VERSION ""

NS_ :

BS_:

BU_:
	NEO
	MCU
	GTW
	EPAS
	DI
	ESP
	SBW
	STW
	APP
	DAS
	XXX

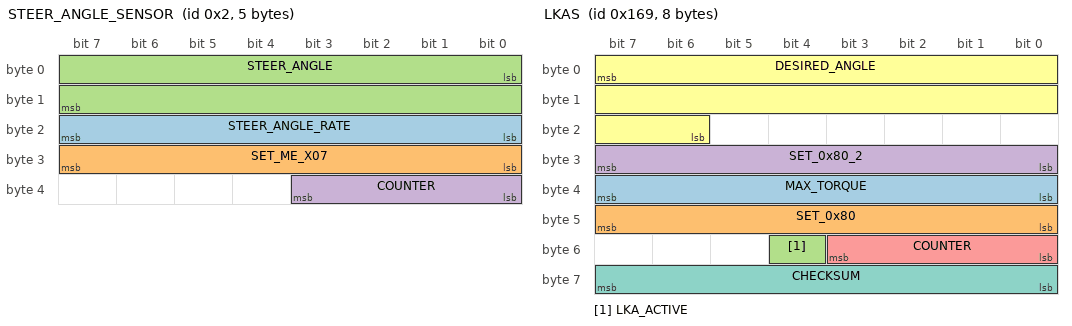
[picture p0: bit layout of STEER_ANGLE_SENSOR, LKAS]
BO_ 2 STEER_ANGLE_SENSOR: 5 XXX
 SG_ STEER_ANGLE_RATE : 16|8@1+ (1,0) [0|255] "" XXX
 SG_ SET_ME_X07 : 24|8@1+ (1,0) [0|255] "" XXX
 SG_ STEER_ANGLE : 0|16@1- (-0.1,0) [0|65535] "" XXX
 SG_ COUNTER : 32|4@1+ (1,0) [0|15] "" XXX

BO_ 361 LKAS: 8 XXX
 SG_ MAX_TORQUE : 39|8@0+ (0.01,0) [0|255] "Nm" XXX
 SG_ SET_0x80 : 47|8@0+ (1,0) [0|255] "" XXX
 SG_ LKA_ACTIVE : 52|1@0+ (1,0) [0|15] "" XXX
 SG_ SET_0x80_2 : 31|8@0+ (1,0) [0|255] "" XXX
 SG_ COUNTER : 51|4@0+ (1,0) [0|15] "" XXX
 SG_ DESIRED_ANGLE : 7|18@0+ (-0.01,1310) [-1311.43|1310] "" XXX
 SG_ CHECKSUM : 63|8@0+ (1,0) [0|255] "" XXX

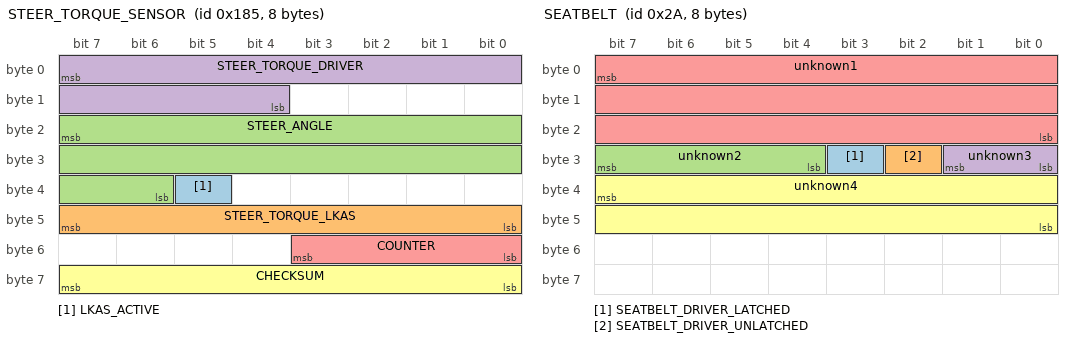
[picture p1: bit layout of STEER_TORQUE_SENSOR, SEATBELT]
BO_ 389 STEER_TORQUE_SENSOR: 8 XXX
 SG_ LKAS_ACTIVE : 37|1@0+ (1,0) [0|3] "" XXX
 SG_ STEER_TORQUE_LKAS : 47|8@0+ (1,0) [0|255] "" XXX
 SG_ STEER_ANGLE : 23|18@0+ (-0.01,1310) [0|262143] "" XXX
 SG_ STEER_TORQUE_DRIVER : 7|12@0+ (-0.01,20.47) [0|4095] "Nm" XXX
 SG_ COUNTER : 51|4@0+ (1,0) [0|15] "" XXX
 SG_ CHECKSUM : 63|8@0+ (1,0) [0|127] "" XXX

BO_ 645 WHEEL_SPEEDS_REAR: 8 XXX
 SG_ WHEEL_SPEED_RR : 7|16@0+ (0.005,0) [0|65535] "KPH" XXX
 SG_ WHEEL_SPEED_RL : 23|16@0+ (0.005,0) [0|65535] "KPH" XXX

BO_ 689 PROPILOT_HUD: 8 XXX
 SG_ LARGE_WARNING_FLASHING : 9|1@0+ (1,0) [0|1] "" XXX
 SG_ SIDE_RADAR_ERROR_FLASHING1 : 10|1@0+ (1,0) [0|1] "" XXX
 SG_ SIDE_RADAR_ERROR_FLASHING2 : 11|1@0+ (1,0) [0|1] "" XXX
 SG_ RIGHT_LANE_YELLOW_FLASH : 12|1@0+ (1,0) [0|1] "" XXX
 SG_ LEFT_LANE_YELLOW_FLASH : 13|1@0+ (1,0) [0|1] "" XXX
 SG_ LEAD_CAR : 14|1@0+ (1,0) [0|1] "" XXX
 SG_ LEAD_CAR_ERROR : 15|1@0+ (1,0) [0|1] "" XXX
 SG_ FRONT_RADAR_ERROR : 16|1@0+ (1,0) [0|1] "" XXX
 SG_ FRONT_RADAR_ERROR_FLASHING : 17|1@0+ (1,0) [0|1] "" XXX
 SG_ RIGHT_LANE_GREEN : 24|1@0+ (1,0) [0|1] "" XXX
 SG_ LEFT_LANE_GREEN : 25|1@0+ (1,0) [0|1] "" XXX
 SG_ SIDE_RADAR_ERROR_FLASHING3 : 27|1@0+ (1,0) [0|1] "" XXX
 SG_ LKAS_ERROR_FLASHING : 29|1@0+ (1,0) [0|1] "" XXX
 SG_ SAFETY_SHIELD_ACTIVE : 44|1@0+ (1,0) [0|1] "" XXX
 SG_ LARGE_STEERING_WHEEL_ICON : 61|2@0+ (1,0) [0|3] "" XXX
 SG_ RIGHT_LANE_GREEN_FLASH : 62|1@0+ (1,0) [0|1] "" XXX
 SG_ LEFT_LANE_GREEN_FLASH : 63|1@0+ (1,0) [0|1] "" XXX
 SG_ FOLLOW_DISTANCE : 3|2@0+ (1,0) [0|3] "" XXX
 SG_ AUDIBLE_TONE : 47|3@0+ (1,0) [0|8] "" XXX
 SG_ SPEED_SET_ICON : 7|2@0+ (1,0) [0|3] "" XXX
 SG_ SMALL_STEERING_WHEEL_ICON : 42|3@0+ (1,0) [0|7] "" XXX
 SG_ SET_SPEED : 39|8@0+ (1,0) [0|255] "" XXX
 SG_ unknown02 : 1|2@0+ (1,0) [0|3] "" XXX
 SG_ unknown05 : 5|2@0+ (1,0) [0|3] "" XXX
 SG_ unknown08 : 8|7@0+ (1,0) [0|63] "" XXX
 SG_ unknown26 : 26|1@0+ (1,0) [0|1] "" XXX
 SG_ unknown28 : 28|1@0+ (1,0) [0|1] "" XXX
 SG_ unknown31 : 31|2@0+ (1,0) [0|3] "" XXX
 SG_ unknown43 : 43|1@0+ (1,0) [0|1] "" XXX
 SG_ unknown55 : 55|8@0+ (1,0) [0|63] "" XXX
 SG_ unknown59 : 59|4@0+ (1,0) [0|15] "" XXX

BO_ 783 CRUISE_STATE: 3 XXX
 SG_ CRUISE_ENABLED : 3|1@0+ (1,0) [0|1] "" XXX

BO_ 1228 PROPILOT_HUD_INFO_MSG: 8 XXX
 SG_ NA_HIGH_ACCEL_TEMP : 0|1@0+ (1,0) [0|1] "" XXX
 SG_ SIDE_RADAR_NA_HIGH_CABIN_TEMP : 8|1@0+ (1,0) [0|1] "" XXX
 SG_ SIDE_RADAR_MALFUNCTION : 11|1@0+ (1,0) [0|1] "" XXX
 SG_ LKAS_MALFUNCTION : 12|1@0+ (1,0) [0|1] "" XXX
 SG_ FRONT_RADAR_MALFUNCTION : 13|1@0+ (1,0) [0|1] "" XXX
 SG_ SIDE_RADAR_NA_CLEAN_REAR_CAMERA : 14|1@0+ (1,0) [0|1] "" XXX
 SG_ NA_POOR_ROAD_CONDITIONS : 16|1@0+ (1,0) [0|1] "" XXX
 SG_ CURRENTLY_UNAVAILABLE : 17|1@0+ (1,0) [0|1] "" XXX
 SG_ SAFETY_SHIELD_OFF : 18|1@0+ (1,0) [0|1] "" XXX
 SG_ FRONT_COLLISION_NA_FRONT_RADAR_OBSTRUCTION : 20|1@0+ (1,0) [0|1] "" XXX
 SG_ PEDAL_MISSAPPLICATION_SYSTEM_ACTIVATED : 24|1@0+ (1,0) [0|1] "" XXX
 SG_ SIDE_IMPACT_NA_RADAR_OBSTRUCTION : 25|1@0+ (1,0) [0|1] "" XXX
 SG_ WARNING_DO_NOT_ENTER : 33|1@0+ (1,0) [0|1] "" XXX
 SG_ SIDE_IMPACT_SYSTEM_OFF : 34|1@0+ (1,0) [0|1] "" XXX
 SG_ SIDE_IMPACT_MALFUNCTION : 35|1@0+ (1,0) [0|1] "" XXX
 SG_ FRONT_COLLISION_MALFUNCTION : 36|1@0+ (1,0) [0|1] "" XXX
 SG_ SIDE_RADAR_MALFUNCTION2 : 37|1@0+ (1,0) [0|1] "" XXX
 SG_ LKAS_MALFUNCTION2 : 38|1@0+ (1,0) [0|1] "" XXX
 SG_ FRONT_RADAR_MALFUNCTION2 : 39|1@0+ (1,0) [0|1] "" XXX
 SG_ PROPILOT_NA_MSGS : 42|3@0+ (1,0) [0|7] "" XXX
 SG_ BOTTOM_MSG : 45|3@0+ (1,0) [0|7] "" XXX
 SG_ HANDS_ON_WHEEL_WARNING : 47|1@0+ (1,0) [0|1] "" XXX
 SG_ WARNING_STEP_ON_BRAKE_NOW : 51|1@0+ (1,0) [0|1] "" XXX
 SG_ PROPILOT_NA_FRONT_CAMERA_OBSTRUCTED : 52|1@0+ (1,0) [0|1] "" XXX
 SG_ PROPILOT_NA_HIGH_CABIN_TEMP : 53|1@0+ (1,0) [0|1] "" XXX
 SG_ WARNING_PROPILOT_MALFUNCTION : 54|1@0+ (1,0) [0|3] "" XXX
 SG_ ACC_UNAVAILABLE_HIGH_CABIN_TEMP : 62|1@0+ (1,0) [0|1] "" XXX
 SG_ ACC_NA_FRONT_CAMERA_IMPARED : 63|1@0+ (1,0) [0|1] "" XXX
 SG_ unknown07 : 7|7@0+ (1,0) [0|127] "" XXX
 SG_ unknown10 : 10|2@0+ (1,0) [0|3] "" XXX
 SG_ unknown15 : 15|1@0+ (1,0) [0|1] "" XXX
 SG_ unknown23 : 23|3@0+ (1,0) [0|7] "" XXX
 SG_ unknown19 : 19|1@0+ (1,0) [0|1] "" XXX
 SG_ unknown31 : 31|6@0+ (1,0) [0|63] "" XXX
 SG_ unknown32 : 32|1@0+ (1,0) [0|1] "" XXX
 SG_ unknown46 : 46|1@0+ (1,0) [0|1] "" XXX
 SG_ unknown50 : 50|3@0+ (1,0) [0|7] "" XXX
 SG_ unknown55 : 55|1@0+ (1,0) [0|1] "" XXX
 SG_ unknown61 : 61|6@0+ (1,0) [0|63] "" XXX

BO_ 1227 LKAS_SETTINGS: 8 XXX
 SG_ LKAS_ENABLED : 51|1@0+ (1,0) [0|1] "" XXX

BO_ 42 SEATBELT: 8 XXX
 SG_ SEATBELT_DRIVER_LATCHED : 27|1@1+ (1,0) [0|3] "" XXX
 SG_ SEATBELT_DRIVER_UNLATCHED : 26|1@0+ (1,0) [0|1] "" XXX
 SG_ unknown2 : 31|4@0+ (1,0) [0|15] "" XXX
 SG_ unknown3 : 24|2@1+ (1,0) [0|3] "" XXX
 SG_ unknown1 : 7|24@0+ (1,0) [0|16777215] "" XXX
 SG_ unknown4 : 39|16@0+ (1,0) [0|65535] "" XXX

BO_ 460 BRAKE_PEDAL: 8 XXX
 SG_ BRAKE_PEDAL : 7|8@0+ (1,0) [0|256] "" XXX

BO_ 569 CRUISE_THROTTLE: 8 XXX
 SG_ GAS_PEDAL_INVERTED : 15|8@0+ (1,0) [0|255] "" XXX
 SG_ GAS_PEDAL : 7|8@0+ (1,0) [0|255] "" XXX
 SG_ CRUISE_AVAILABLE : 17|1@0+ (1,0) [0|1] "" XXX
 SG_ unsure1 : 23|6@0+ (1,0) [0|63] "" XXX
 SG_ unsure2 : 16|1@0+ (1,0) [0|1] "" XXX
 SG_ unsure3 : 31|2@0+ (1,0) [0|3] "" XXX
 SG_ NO_BUTTON_PRESSED : 29|1@0+ (1,0) [0|1] "" XXX
 SG_ RES_BUTTON : 28|1@0+ (1,0) [0|1] "" XXX
 SG_ SET_BUTTON : 27|1@0+ (1,0) [0|1] "" XXX
 SG_ FOLLOW_DISTANCE_BUTTON : 26|1@0+ (1,0) [0|1] "" XXX
 SG_ CANCEL_BUTTON : 25|1@0+ (1,0) [0|1] "" XXX
 SG_ PROPILOT_BUTTON : 24|1@0+ (1,0) [0|1] "" XXX
 SG_ USER_BRAKE_PRESSED : 37|1@0+ (1,0) [0|1] "" XXX
 SG_ COUNTER : 32|2@1+ (1,0) [0|3] "" XXX
 SG_ unsure5 : 47|8@0+ (1,0) [0|255] "" XXX
 SG_ unsure6 : 55|8@0+ (1,0) [0|255] "" XXX
 SG_ unsure7 : 63|8@0+ (1,0) [0|255] "" XXX

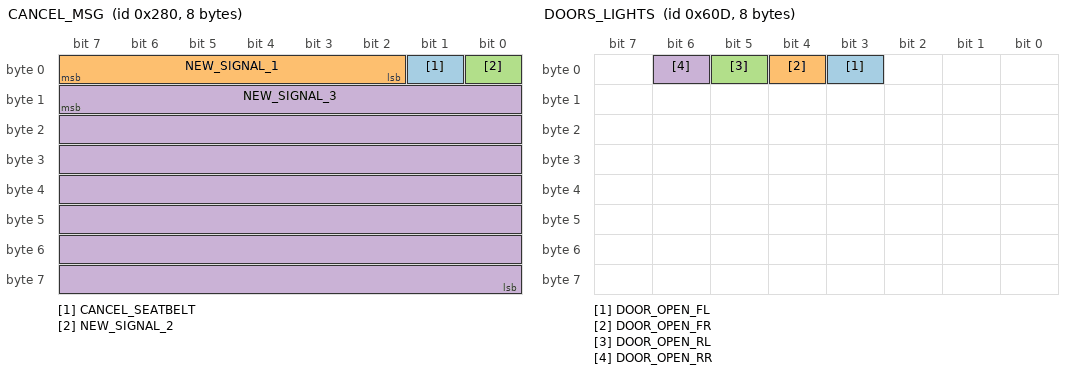
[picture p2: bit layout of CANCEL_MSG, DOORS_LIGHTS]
BO_ 640 CANCEL_MSG: 8 XXX
  SG_ CANCEL_SEATBELT : 1|1@0+ (1,0) [0|1] "" XXX
  SG_ NEW_SIGNAL_1 : 7|6@0+ (1,0) [0|63] "" XXX
  SG_ NEW_SIGNAL_2 : 0|1@0+ (1,0) [0|1] "" XXX
  SG_ NEW_SIGNAL_3 : 15|56@0+ (1,0) [0|72057594037927940] "" XXX

BO_ 644 WHEEL_SPEEDS_FRONT: 8 XXX
 SG_ WHEEL_SPEED_FR : 7|16@0+ (0.005,0) [0|65535] "KPH" XXX
 SG_ WHEEL_SPEED_FL : 23|16@0+ (0.005,0) [0|65535] "KPH" XXX

BO_ 852 ESP: 8 XXX
 SG_ ESP_DISABLED : 38|1@0+ (1,0) [0|1] "" XXX

BO_ 853 HUD_SETTINGS: 8 XXX
 SG_ SPEED_MPH : 37|1@0+ (1,0) [0|1] "" XXX

BO_ 856 LIGHTS: 8 XXX
 SG_ LEFT_BLINKER : 17|1@0+ (1,0) [0|1] "" XXX
 SG_ RIGHT_BLINKER : 18|1@0+ (1,0) [0|1] "" XXX

BO_ 1057 GEARBOX: 3 XXX
 SG_ GEAR_SHIFTER : 5|3@0+ (1,0) [0|255] "" XXX

BO_ 1549 DOORS_LIGHTS: 8 XXX
 SG_ DOOR_OPEN_FL : 3|1@0+ (1,0) [0|1] "" XXX
 SG_ DOOR_OPEN_FR : 4|1@0+ (1,0) [0|1] "" XXX
 SG_ DOOR_OPEN_RL : 5|1@0+ (1,0) [0|1] "" XXX
 SG_ DOOR_OPEN_RR : 6|1@0+ (1,0) [0|1] "" XXX

BU_: XXX X

CM_ SG_ 80 Checksumme_Airbag_1 "Checksum Airbag_1";
CM_ SG_ 80 Zaehler_Airbag_1 "Counter Airbag_1";

CM_ SG_ 210 LM_Offset "centiNewton-meters for ease of calculation without FP math in Panda";
CM_ SG_ 210 Vib_Amp "Steering wheel haptic, amplitude";
CM_ SG_ 210 Vib_Freq "Steering wheel haptic, frequency";

CM_ SG_ 416 Zaehler_Bremse_1 "Counter Bremse_1";

CM_ SG_ 640 inneres_Motor_Moment "Engine Indicated Torque";
CM_ SG_ 640 Fahrerwunschmoment "Driver Requested Torque";
CM_ SG_ 640 mechanisches_Motor_Verlustmomen "Mechanical Torque Loss";
CM_ SG_ 640 Fahrpedalwert_oder_Drosselklapp "Accelerator Pedal or Throttle Position";
CM_ SG_ 640 Motordrehzahl "Engine Speed";
CM_ SG_ 640 Momentenangaben_ungenau "Approximate Torque Values";
CM_ SG_ 640 inneres_Motor_Moment_ohne_exter "Inner torque without external";

CM_ SG_ 644 MOB_CHECKSUM "Checksum MOB";
CM_ SG_ 644 MOB_COUNTER "Counter MOB";

CM_ SG_ 648 Minimales_Motormoment_bei_Zuend "Minimum Torque Adjustment";
CM_ SG_ 648 Begrenzungsmoment "Maximum Inner Torque";
CM_ SG_ 648 Bremstestschalter "Brake Test Switch";
CM_ SG_ 648 Soll_Geschwindigkeit_bei_GRA_Be "Desired Vehicle Speed";
CM_ SG_ 648 Bremslichtschalter "Brake Light Switch";
CM_ SG_ 648 Leerlaufsolldrehzahl__Motor_2_ "Target Idle Speed";
CM_ SG_ 648 Fahrzeuggeschwindigkeit "Vehicle Speed";
CM_ SG_ 648 Kuehlmitteltemperatur__Motor_2_ "Coolant Temperature";

CM_ SG_ 896 Drosselklappenpoti "Throttle Position";
CM_ SG_ 896 Motor_Wunschdrehzahl "Desired engine speed";
CM_ SG_ 896 Motordrehzahlbeeinflussung "Shift Target Influence";
CM_ SG_ 896 Fahrpedal_Rohsignal "Accelerator Pedal Position";
CM_ SG_ 896 Ansauglufttemperatur "Intake Air Temperature";
CM_ SG_ 896 Kein_E_Gas "ETB flag";
CM_ SG_ 896 Kein_Start_Stop "Start/stop flag";
CM_ SG_ 896 Rad_Wunschmoment "Desired wheel torque";

CM_ SG_ 912 GK1_Fa_Tuerkont "Status of the driver's door rotary latch";
CM_ SG_ 912 BSK_HL_geoeffnet "Status of the rear left door rotary latch";
CM_ SG_ 912 BSK_HR_geoeffnet "Status of the rear right door rotary latch";
CM_ SG_ 912 BSK_BT_geoeffnet "Status of the passenger door rotary latch";
CM_ SG_ 912 BSK_HD_Hauptraste "Status of trunk lid main detent";

CM_ SG_ 1088 Zaehler_Getriebe_1 "Counter Getriebe_1";
CM_ SG_ 1088 Waehlhebelposition__Getriebe_1_ "Gear Selector Position";
CM_ SG_ 1088 inneres_Soll_Motormoment "Desired Inner Torque";
CM_ SG_ 1088 Schaltabsicht "Shift Intent";
CM_ SG_ 1088 Wandlerverlustmoment "Converter Torque Loss";

CM_ SG_ 1056 Fehlerstatus_Aussentemp__4_1 "ambient temp error";
CM_ SG_ 1056 Fehlerstatus_Oeltemperatur_4_1 "oil temp error";
CM_ SG_ 1056 Fehlerst__Kuehlmitteltemp__4_1 "water temp error";
CM_ SG_ 1056 Aussentemperatur_gefiltert "outside temp, filtered";
CM_ SG_ 1056 Oeltemperatur_4_1 "kombi oil temperature";
CM_ SG_ 1056 Kuehlmitteltemp__4_1__Kombi_2_ "kombi coolant temperature";

CM_ SG_ 1096 Zaehler_Waehlhebel_1 "Counter Waehlhebel_1";

CM_ SG_ 1152 CHECKSUM "Checksum Motor_5";
CM_ SG_ 1152 Anlasser_Ausspuren "Starter Disable";
CM_ SG_ 1152 Anlasser_Freigabe "Starter Release";
CM_ SG_ 1152 Klimadrucksignal__Motor_5_ "Air conditioning pressure signal";
CM_ SG_ 1152 Kraftstoffverbrauchssignal "Fuel consumption signal";
CM_ SG_ 1152 K_hlerluefteransteuerung "Cooling fan control signal";
CM_ SG_ 1152 Klimakompressor_Leistungsreduzi "Air conditioning compressor power reduction flag";
CM_ SG_ 1152 Klimakompressor_aus__Motor_5_ "Air conditioning compressor";
CM_ SG_ 1152 Anlasser_Freigabe "Starter release";
CM_ SG_ 1152 OBD_2_Lampe "OBD light";
CM_ SG_ 1152 E_Gas_Lampe "ETB light";
CM_ SG_ 1152 Ladekontroll_Lampe "Charge light";
CM_ SG_ 1152 Vorgluehlampe__Motor_5_ "Glow light";

CM_ SG_ 1160 Zaehler_Motor_6 "Counter Motor_6";
CM_ SG_ 1160 Hoeheninfo__Motor_6_ "Altitude Correction";
CM_ SG_ 1160 Istmoment_f_r_Getriebe "Actual torque for gear";
CM_ SG_ 1160 Sollmoment_f_r_Getriebe "Target torque for gearbox";
CM_ SG_ 1160 Checksumme_Motor_6 "Checksum Motor_6";
CM_ SG_ 1160 GRA_Sollbeschleunigung "GRA target acceleration";
CM_ SG_ 1160 Ruckmeldung_Momenten "Feedback torque-integral gear intervention";

CM_ SG_ 1344 Zahler_Getriebe_2 "Counter Getriebe_2";
CM_ SG_ 1344 Hochschaltlampe "Upshift Flag";

CM_ SG_ 1386 ACA_V_Wunsch "255=unset";

CM_ SG_ 1408 Zaehler_Motor_Flexia "Counter Motor_Flexia";
CM_ SG_ 1408 Verbrennungsart "Type of combustion";
CM_ SG_ 1408 Max_Drehmoment "Maximum torque";
CM_ SG_ 1408 Drehzahl_MaxNorm "RPM of maximum torque";
CM_ SG_ 1408 Hubraum "Displacement";
CM_ SG_ 1408 Anzahl_Zylinder "Number of cylinders";
CM_ SG_ 1408 Anzahl_Ventile "Number of valves";
CM_ SG_ 1408 Ansaugsystem "Induction System";
CM_ SG_ 1408 Motorleistung "Maximum engine power";

CM_ SG_ 1416 Ladedruck "Boost Pressure";
CM_ SG_ 1416 Motordrehzahlgradient "Engine speed gradient";
CM_ SG_ 1416 Hoeheninfo__Motor_7_ "Altitude correction factor";
CM_ SG_ 1416 Oltemperatur "Oil temperature";

CM_ SG_ 1470 LDW_Direction "0=right,1=left";
CM_ SG_ 1470 XX_DLCORTLC1 "Might be DLC or TLC";
CM_ SG_ 1470 XX_DLCORTLC2 "Might be DLC or TLC, might have wrong size";

CM_ SG_ 1550 MFA_v_Signal_02 "0=km/h, 1=mph";

VAL_ 368 Gear_State 4 "D" 2 "N" 1 "R" 0 "P" ;
